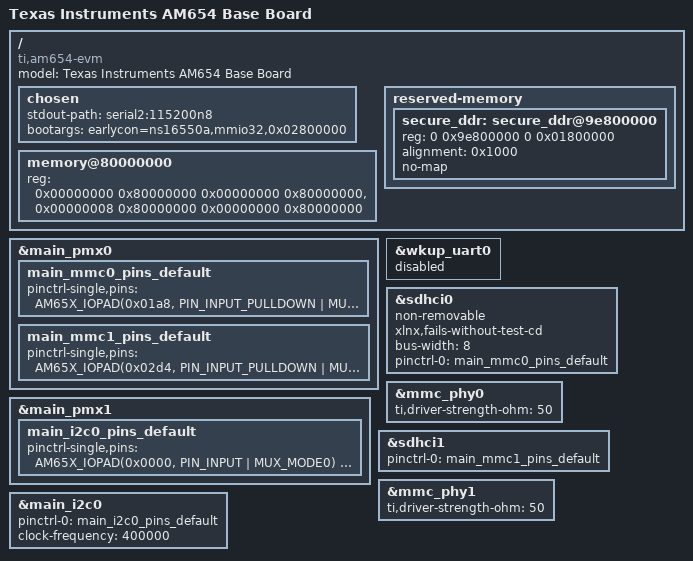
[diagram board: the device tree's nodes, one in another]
// SPDX-License-Identifier: GPL-2.0
/*
 * Copyright (C) 2016-2018 Texas Instruments Incorporated - http://www.ti.com/
 */

/dts-v1/;

#include "k3-am654.dtsi"

/ {
	compatible =  "ti,am654-evm", "ti,am654";
	model = "Texas Instruments AM654 Base Board";

	chosen {
		stdout-path = "serial2:115200n8";
		bootargs = "earlycon=ns16550a,mmio32,0x02800000";
	};

	memory@80000000 {
		device_type = "memory";
		/* 4G RAM */
		reg = <0x00000000 0x80000000 0x00000000 0x80000000>,
		      <0x00000008 0x80000000 0x00000000 0x80000000>;
	};

	reserved-memory {
		#address-cells = <2>;
		#size-cells = <2>;
		ranges;
		secure_ddr: secure_ddr@9e800000 {
			reg = <0 0x9e800000 0 0x01800000>; /* for OP-TEE */
			alignment = <0x1000>;
			no-map;
		};
	};
};

&main_pmx0 {
	main_mmc0_pins_default: main_mmc0_pins_default {
		pinctrl-single,pins = <
			AM65X_IOPAD(0x01a8, PIN_INPUT_PULLDOWN | MUX_MODE0) /* (B25) MMC0_CLK */
			AM65X_IOPAD(0x01aC, PIN_INPUT_PULLUP | MUX_MODE0) /* (B27) MMC0_CMD */
			AM65X_IOPAD(0x01a4, PIN_INPUT_PULLUP | MUX_MODE0) /* (A26) MMC0_DAT0 */
			AM65X_IOPAD(0x01a0, PIN_INPUT_PULLUP | MUX_MODE0) /* (E25) MMC0_DAT1 */
			AM65X_IOPAD(0x019c, PIN_INPUT_PULLUP | MUX_MODE0) /* (C26) MMC0_DAT2 */
			AM65X_IOPAD(0x0198, PIN_INPUT_PULLUP | MUX_MODE0) /* (A25) MMC0_DAT3 */
			AM65X_IOPAD(0x0194, PIN_INPUT_PULLUP | MUX_MODE0) /* (E24) MMC0_DAT4 */
			AM65X_IOPAD(0x0190, PIN_INPUT_PULLUP | MUX_MODE0) /* (A24) MMC0_DAT5 */
			AM65X_IOPAD(0x018c, PIN_INPUT_PULLUP | MUX_MODE0) /* (B26) MMC0_DAT6 */
			AM65X_IOPAD(0x0188, PIN_INPUT_PULLUP | MUX_MODE0) /* (D25) MMC0_DAT7 */
			AM65X_IOPAD(0x01b0, PIN_INPUT | MUX_MODE0) /* (C25) MMC0_DS */
		>;
	};

	main_mmc1_pins_default: main_mmc1_pins_default {
		pinctrl-single,pins = <
			AM65X_IOPAD(0x02d4, PIN_INPUT_PULLDOWN | MUX_MODE0) /* (C27) MMC1_CLK */
			AM65X_IOPAD(0x02d8, PIN_INPUT_PULLUP | MUX_MODE0) /* (C28) MMC1_CMD */
			AM65X_IOPAD(0x02d0, PIN_INPUT_PULLUP | MUX_MODE0) /* (D28) MMC1_DAT0 */
			AM65X_IOPAD(0x02cc, PIN_INPUT_PULLUP | MUX_MODE0) /* (E27) MMC1_DAT1 */
			AM65X_IOPAD(0x02c8, PIN_INPUT_PULLUP | MUX_MODE0) /* (D26) MMC1_DAT2 */
			AM65X_IOPAD(0x02c4, PIN_INPUT_PULLUP | MUX_MODE0) /* (D27) MMC1_DAT3 */
			AM65X_IOPAD(0x02dc, PIN_INPUT_PULLUP | MUX_MODE0) /* (B24) MMC1_SDCD */
			AM65X_IOPAD(0x02e0, PIN_INPUT | MUX_MODE0) /* (C24) MMC1_SDWP */
		>;
	};
};

&main_pmx1 {
	main_i2c0_pins_default: main_i2c0_pins_default {
		pinctrl-single,pins = <
			AM65X_IOPAD(0x0000, PIN_INPUT | MUX_MODE0) /* (D20) I2C0_SCL */
			AM65X_IOPAD(0x0004, PIN_INPUT | MUX_MODE0) /* (C21) I2C0_SDA */
		>;
	};
};


&wkup_uart0 {
	/* Wakeup UART is used by System firmware */
	status = "disabled";
};

&sdhci0 {
	status = "okay";
	non-removable;
	xlnx,fails-without-test-cd;
	bus-width = <8>;
	pinctrl-names = "default";
	pinctrl-0 = <&main_mmc0_pins_default>;
};

&mmc_phy0 {
	status = "okay";
	ti,driver-strength-ohm = <50>;
};

&sdhci1 {
	status = "okay";
	pinctrl-names = "default";
	pinctrl-0 = <&main_mmc1_pins_default>;
};

&mmc_phy1 {
	status = "okay";
	ti,driver-strength-ohm = <50>;
};

&main_i2c0 {
	#address-cells = <1>;
	#size-cells = <0>;

	pinctrl-names = "default";
	pinctrl-0 = <&main_i2c0_pins_default>;
	status = "okay";
	clock-frequency = <400000>;
};
